AUTOSAR XML (schema 4-0-3)
standard types defined: Boolean, UInt16, UInt32, UInt8
package /AUTOSAR_Platform/DataConstrs
  range DC_Boolean: raw 0..1
  range DC_UInt16: raw 0..65535
  range DC_UInt8: raw 0..255
package /PATAC/MSM/ComponentTypes
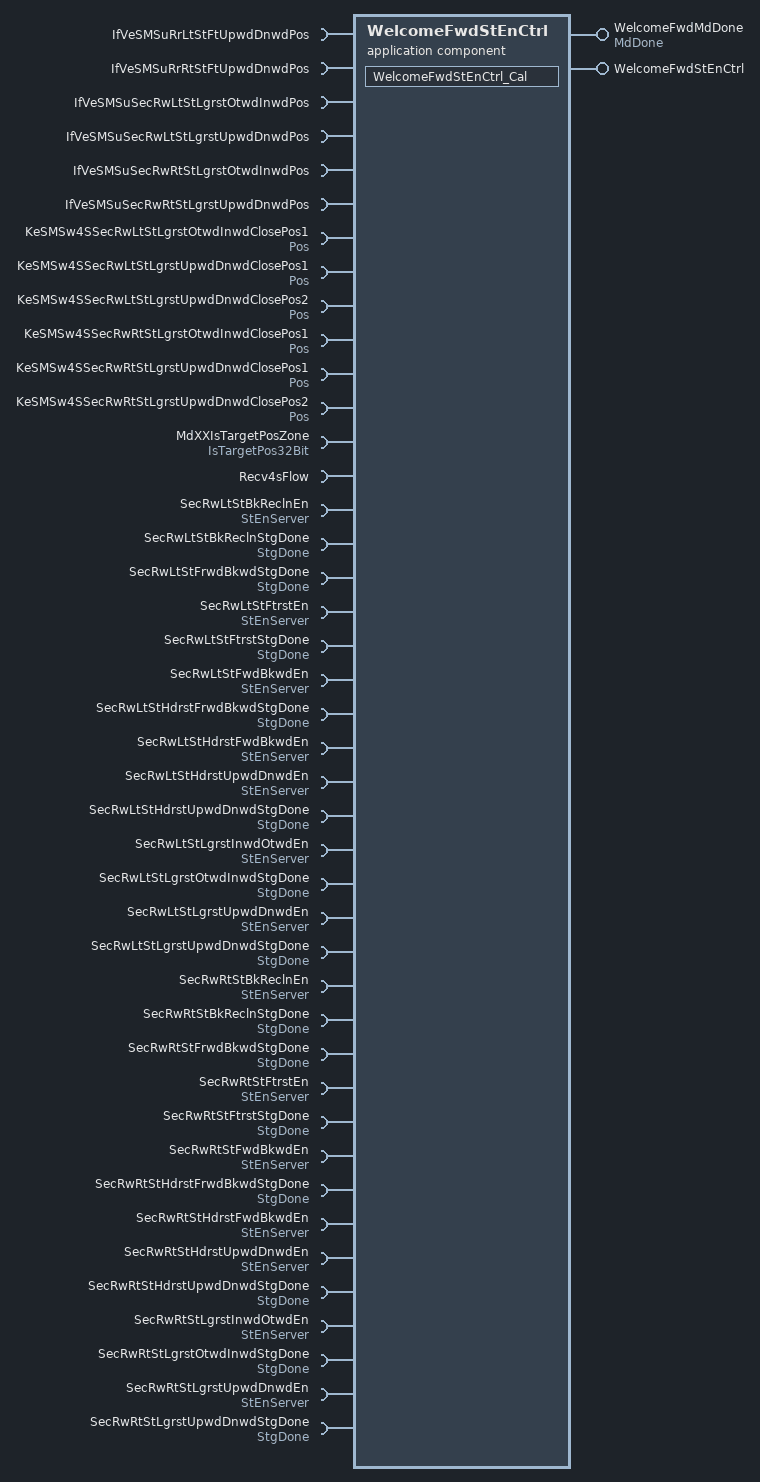
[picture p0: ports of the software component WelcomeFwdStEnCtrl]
  application sw component type WelcomeFwdStEnCtrl
    provide port WelcomeFwdMdDone: nonqueued-sender-com-spec{data-element=MdDone/Val, init-value=0}, provided-interface=MdDone
    provide port WelcomeFwdStEnCtrl: server-com-spec{operation=WelcomeFwdStEnCtrl/Cal, queue-length=1}, provided-interface=WelcomeFwdStEnCtrl
    42 x require port:
      IfVeSMSuRrLtStFtUpwdDnwdPos: nonqueued-receiver-com-spec{data-element=IfVeSMSuRrLtStFtUpwdDnwdPos/Val, filter=data-filter-type=ALWAYS, init-value=0}, required-interface=IfVeSMSuRrLtStFtUpwdDnwdPos
      IfVeSMSuRrRtStFtUpwdDnwdPos: nonqueued-receiver-com-spec{data-element=IfVeSMSuRrRtStFtUpwdDnwdPos/Val, filter=data-filter-type=ALWAYS, init-value=0}, required-interface=IfVeSMSuRrRtStFtUpwdDnwdPos
      IfVeSMSuSecRwLtStLgrstOtwdInwdPos: nonqueued-receiver-com-spec{data-element=IfVeSMSuSecRwLtStLgrstOtwdInwdPos/Val, filter=data-filter-type=ALWAYS, init-value=0}, required-interface=IfVeSMSuSecRwLtStLgrstOtwdInwdPos
      IfVeSMSuSecRwLtStLgrstUpwdDnwdPos: nonqueued-receiver-com-spec{data-element=IfVeSMSuSecRwLtStLgrstUpwdDnwdPos/Val, filter=data-filter-type=ALWAYS, init-value=0}, required-interface=IfVeSMSuSecRwLtStLgrstUpwdDnwdPos
      IfVeSMSuSecRwRtStLgrstOtwdInwdPos: nonqueued-receiver-com-spec{data-element=IfVeSMSuSecRwRtStLgrstOtwdInwdPos/Val, filter=data-filter-type=ALWAYS, init-value=0}, required-interface=IfVeSMSuSecRwRtStLgrstOtwdInwdPos
      IfVeSMSuSecRwRtStLgrstUpwdDnwdPos: nonqueued-receiver-com-spec{data-element=IfVeSMSuSecRwRtStLgrstUpwdDnwdPos/Val, filter=data-filter-type=ALWAYS, init-value=0}, required-interface=IfVeSMSuSecRwRtStLgrstUpwdDnwdPos
      KeSMSw4SSecRwLtStLgrstOtwdInwdClosePos1: parameter-require-com-spec{init-value=0, parameter=Val}, required-interface=Pos
      KeSMSw4SSecRwLtStLgrstUpwdDnwdClosePos1: parameter-require-com-spec{init-value=0, parameter=Val}, required-interface=Pos
      KeSMSw4SSecRwLtStLgrstUpwdDnwdClosePos2: parameter-require-com-spec{init-value=0, parameter=Val}, required-interface=Pos
      KeSMSw4SSecRwRtStLgrstOtwdInwdClosePos1: parameter-require-com-spec{init-value=0, parameter=Val}, required-interface=Pos
      KeSMSw4SSecRwRtStLgrstUpwdDnwdClosePos1: parameter-require-com-spec{init-value=0, parameter=Val}, required-interface=Pos
      KeSMSw4SSecRwRtStLgrstUpwdDnwdClosePos2: parameter-require-com-spec{init-value=0, parameter=Val}, required-interface=Pos
      MdXXIsTargetPosZone: nonqueued-receiver-com-spec{data-element=IsTargetPos32Bit/Val, filter=data-filter-type=ALWAYS, init-value=0}, required-interface=IsTargetPos32Bit
      Recv4sFlow: client-com-spec=Recv4sFlow/Cal, required-interface=Recv4sFlow
      SecRwLtStBkReclnEn: required-com-specs=[Clear, Get, Set], required-interface=StEnServer
      SecRwLtStBkReclnStgDone: nonqueued-receiver-com-spec{data-element=StgDone/Val, filter=data-filter-type=ALWAYS, init-value=0}, required-interface=StgDone
      SecRwLtStFrwdBkwdStgDone: nonqueued-receiver-com-spec{data-element=StgDone/Val, filter=data-filter-type=ALWAYS, init-value=0}, required-interface=StgDone
      SecRwLtStFtrstEn: required-com-specs=[Clear, Get, Set], required-interface=StEnServer
      SecRwLtStFtrstStgDone: nonqueued-receiver-com-spec{data-element=StgDone/Val, filter=data-filter-type=ALWAYS, init-value=0}, required-interface=StgDone
      SecRwLtStFwdBkwdEn: required-com-specs=[Clear, Get, Set], required-interface=StEnServer
      SecRwLtStHdrstFrwdBkwdStgDone: nonqueued-receiver-com-spec{data-element=StgDone/Val, filter=data-filter-type=ALWAYS, init-value=0}, required-interface=StgDone
      SecRwLtStHdrstFwdBkwdEn: required-com-specs=[Clear, Get, Set], required-interface=StEnServer
      SecRwLtStHdrstUpwdDnwdEn: required-com-specs=[Clear, Get, Set], required-interface=StEnServer
      SecRwLtStHdrstUpwdDnwdStgDone: nonqueued-receiver-com-spec{data-element=StgDone/Val, filter=data-filter-type=ALWAYS, init-value=0}, required-interface=StgDone
      SecRwLtStLgrstInwdOtwdEn: required-com-specs=[Clear, Get, Set], required-interface=StEnServer
      SecRwLtStLgrstOtwdInwdStgDone: nonqueued-receiver-com-spec{data-element=StgDone/Val, filter=data-filter-type=ALWAYS, init-value=0}, required-interface=StgDone
      SecRwLtStLgrstUpwdDnwdEn: required-com-specs=[Clear, Get, Set], required-interface=StEnServer
      SecRwLtStLgrstUpwdDnwdStgDone: nonqueued-receiver-com-spec{data-element=StgDone/Val, filter=data-filter-type=ALWAYS, init-value=0}, required-interface=StgDone
      SecRwRtStBkReclnEn: required-com-specs=[Clear, Get, Set], required-interface=StEnServer
      SecRwRtStBkReclnStgDone: nonqueued-receiver-com-spec{data-element=StgDone/Val, filter=data-filter-type=ALWAYS, init-value=0}, required-interface=StgDone
      SecRwRtStFrwdBkwdStgDone: nonqueued-receiver-com-spec{data-element=StgDone/Val, filter=data-filter-type=ALWAYS, init-value=0}, required-interface=StgDone
      SecRwRtStFtrstEn: required-com-specs=[Clear, Get, Set], required-interface=StEnServer
      SecRwRtStFtrstStgDone: nonqueued-receiver-com-spec{data-element=StgDone/Val, filter=data-filter-type=ALWAYS, init-value=0}, required-interface=StgDone
      SecRwRtStFwdBkwdEn: required-com-specs=[Clear, Get, Set], required-interface=StEnServer
      SecRwRtStHdrstFrwdBkwdStgDone: nonqueued-receiver-com-spec{data-element=StgDone/Val, filter=data-filter-type=ALWAYS, init-value=0}, required-interface=StgDone
      SecRwRtStHdrstFwdBkwdEn: required-com-specs=[Clear, Get, Set], required-interface=StEnServer
      SecRwRtStHdrstUpwdDnwdEn: required-com-specs=[Clear, Get, Set], required-interface=StEnServer
      SecRwRtStHdrstUpwdDnwdStgDone: nonqueued-receiver-com-spec{data-element=StgDone/Val, filter=data-filter-type=ALWAYS, init-value=0}, required-interface=StgDone
      SecRwRtStLgrstInwdOtwdEn: required-com-specs=[Clear, Get, Set], required-interface=StEnServer
      SecRwRtStLgrstOtwdInwdStgDone: nonqueued-receiver-com-spec{data-element=StgDone/Val, filter=data-filter-type=ALWAYS, init-value=0}, required-interface=StgDone
      SecRwRtStLgrstUpwdDnwdEn: required-com-specs=[Clear, Get, Set], required-interface=StEnServer
      SecRwRtStLgrstUpwdDnwdStgDone: nonqueued-receiver-com-spec{data-element=StgDone/Val, filter=data-filter-type=ALWAYS, init-value=0}, required-interface=StgDone
    behavior WelcomeFwdStEnCtrl_InternalBehavior
      operation invoked event OIT_WelcomeFwdStEnCtrl_Cal_WelcomeFwdStEnCtrl_Cal: start-on-event=WelcomeFwdStEnCtrl_Cal, operation=WelcomeFwdStEnCtrl.Cal
      runnable WelcomeFwdStEnCtrl_Cal
        data-receive-point-by-arguments:
          21 x access:
            REC_IfVeSMSuRrLtStFtUpwdDnwdPos_Val: accessed-variable=IfVeSMSuRrLtStFtUpwdDnwdPos.Val
            REC_IfVeSMSuRrRtStFtUpwdDnwdPos_Val: accessed-variable=IfVeSMSuRrRtStFtUpwdDnwdPos.Val
            REC_IfVeSMSuSecRwLtStLgrstOtwdInwdPos_Val: accessed-variable=IfVeSMSuSecRwLtStLgrstOtwdInwdPos.Val
            REC_IfVeSMSuSecRwLtStLgrstUpwdDnwdPos_Val: accessed-variable=IfVeSMSuSecRwLtStLgrstUpwdDnwdPos.Val
            REC_IfVeSMSuSecRwRtStLgrstOtwdInwdPos_Val: accessed-variable=IfVeSMSuSecRwRtStLgrstOtwdInwdPos.Val
            REC_IfVeSMSuSecRwRtStLgrstUpwdDnwdPos_Val: accessed-variable=IfVeSMSuSecRwRtStLgrstUpwdDnwdPos.Val
            REC_MdXXIsTargetPosZone_Val: accessed-variable=MdXXIsTargetPosZone.Val
            REC_SecRwLtStBkReclnStgDone_Val: accessed-variable=SecRwLtStBkReclnStgDone.Val
            REC_SecRwLtStFrwdBkwdStgDone_Val: accessed-variable=SecRwLtStFrwdBkwdStgDone.Val
            REC_SecRwLtStFtrstStgDone_Val: accessed-variable=SecRwLtStFtrstStgDone.Val
            REC_SecRwLtStHdrstFrwdBkwdStgDone_Val: accessed-variable=SecRwLtStHdrstFrwdBkwdStgDone.Val
            REC_SecRwLtStHdrstUpwdDnwdStgDone_Val: accessed-variable=SecRwLtStHdrstUpwdDnwdStgDone.Val
            REC_SecRwLtStLgrstOtwdInwdStgDone_Val: accessed-variable=SecRwLtStLgrstOtwdInwdStgDone.Val
            REC_SecRwLtStLgrstUpwdDnwdStgDone_Val: accessed-variable=SecRwLtStLgrstUpwdDnwdStgDone.Val
            REC_SecRwRtStBkReclnStgDone_Val: accessed-variable=SecRwRtStBkReclnStgDone.Val
            REC_SecRwRtStFrwdBkwdStgDone_Val: accessed-variable=SecRwRtStFrwdBkwdStgDone.Val
            REC_SecRwRtStFtrstStgDone_Val: accessed-variable=SecRwRtStFtrstStgDone.Val
            REC_SecRwRtStHdrstFrwdBkwdStgDone_Val: accessed-variable=SecRwRtStHdrstFrwdBkwdStgDone.Val
            REC_SecRwRtStHdrstUpwdDnwdStgDone_Val: accessed-variable=SecRwRtStHdrstUpwdDnwdStgDone.Val
            REC_SecRwRtStLgrstOtwdInwdStgDone_Val: accessed-variable=SecRwRtStLgrstOtwdInwdStgDone.Val
            REC_SecRwRtStLgrstUpwdDnwdStgDone_Val: accessed-variable=SecRwRtStLgrstUpwdDnwdStgDone.Val
        data-send-points:
          access SEND_WelcomeFwdMdDone_Val: accessed-variable=WelcomeFwdMdDone.Val
        6 x parameter access:
          PA_KeSMSw4SSecRwLtStLgrstOtwdInwdClosePos1_Val: accessed-parameter=KeSMSw4SSecRwLtStLgrstOtwdInwdClosePos1.Val
          PA_KeSMSw4SSecRwLtStLgrstUpwdDnwdClosePos1_Val: accessed-parameter=KeSMSw4SSecRwLtStLgrstUpwdDnwdClosePos1.Val
          PA_KeSMSw4SSecRwLtStLgrstUpwdDnwdClosePos2_Val: accessed-parameter=KeSMSw4SSecRwLtStLgrstUpwdDnwdClosePos2.Val
          PA_KeSMSw4SSecRwRtStLgrstOtwdInwdClosePos1_Val: accessed-parameter=KeSMSw4SSecRwRtStLgrstOtwdInwdClosePos1.Val
          PA_KeSMSw4SSecRwRtStLgrstUpwdDnwdClosePos1_Val: accessed-parameter=KeSMSw4SSecRwRtStLgrstUpwdDnwdClosePos1.Val
          PA_KeSMSw4SSecRwRtStLgrstUpwdDnwdClosePos2_Val: accessed-parameter=KeSMSw4SSecRwRtStLgrstUpwdDnwdClosePos2.Val
        29 x sync call, all with timeout=0:
          SC_Recv4sFlow_Cal: operation=Recv4sFlow.Cal
          SC_SecRwLtStBkReclnEn_Clear: operation=SecRwLtStBkReclnEn.Clear
          SC_SecRwLtStBkReclnEn_Set: operation=SecRwLtStBkReclnEn.Set
          SC_SecRwLtStFtrstEn_Clear: operation=SecRwLtStFtrstEn.Clear
          SC_SecRwLtStFtrstEn_Set: operation=SecRwLtStFtrstEn.Set
          SC_SecRwLtStFwdBkwdEn_Clear: operation=SecRwLtStFwdBkwdEn.Clear
          SC_SecRwLtStFwdBkwdEn_Set: operation=SecRwLtStFwdBkwdEn.Set
          SC_SecRwLtStHdrstFwdBkwdEn_Clear: operation=SecRwLtStHdrstFwdBkwdEn.Clear
          SC_SecRwLtStHdrstFwdBkwdEn_Set: operation=SecRwLtStHdrstFwdBkwdEn.Set
          SC_SecRwLtStHdrstUpwdDnwdEn_Clear: operation=SecRwLtStHdrstUpwdDnwdEn.Clear
          SC_SecRwLtStHdrstUpwdDnwdEn_Set: operation=SecRwLtStHdrstUpwdDnwdEn.Set
          SC_SecRwLtStLgrstInwdOtwdEn_Clear: operation=SecRwLtStLgrstInwdOtwdEn.Clear
          SC_SecRwLtStLgrstInwdOtwdEn_Set: operation=SecRwLtStLgrstInwdOtwdEn.Set
          SC_SecRwLtStLgrstUpwdDnwdEn_Clear: operation=SecRwLtStLgrstUpwdDnwdEn.Clear
          SC_SecRwLtStLgrstUpwdDnwdEn_Set: operation=SecRwLtStLgrstUpwdDnwdEn.Set
          SC_SecRwRtStBkReclnEn_Clear: operation=SecRwRtStBkReclnEn.Clear
          SC_SecRwRtStBkReclnEn_Set: operation=SecRwRtStBkReclnEn.Set
          SC_SecRwRtStFtrstEn_Clear: operation=SecRwRtStFtrstEn.Clear
          SC_SecRwRtStFtrstEn_Set: operation=SecRwRtStFtrstEn.Set
          SC_SecRwRtStFwdBkwdEn_Clear: operation=SecRwRtStFwdBkwdEn.Clear
          SC_SecRwRtStFwdBkwdEn_Set: operation=SecRwRtStFwdBkwdEn.Set
          SC_SecRwRtStHdrstFwdBkwdEn_Clear: operation=SecRwRtStHdrstFwdBkwdEn.Clear
          SC_SecRwRtStHdrstFwdBkwdEn_Set: operation=SecRwRtStHdrstFwdBkwdEn.Set
          SC_SecRwRtStHdrstUpwdDnwdEn_Clear: operation=SecRwRtStHdrstUpwdDnwdEn.Clear
          SC_SecRwRtStHdrstUpwdDnwdEn_Set: operation=SecRwRtStHdrstUpwdDnwdEn.Set
          SC_SecRwRtStLgrstInwdOtwdEn_Clear: operation=SecRwRtStLgrstInwdOtwdEn.Clear
          SC_SecRwRtStLgrstInwdOtwdEn_Set: operation=SecRwRtStLgrstInwdOtwdEn.Set
          SC_SecRwRtStLgrstUpwdDnwdEn_Clear: operation=SecRwRtStLgrstUpwdDnwdEn.Clear
          SC_SecRwRtStLgrstUpwdDnwdEn_Set: operation=SecRwRtStLgrstUpwdDnwdEn.Set
  swc implementation WelcomeFwdStEnCtrl_Implementation: behavior=WelcomeFwdStEnCtrl_InternalBehavior
    code-descriptors:
      code Default: artifact-descriptors=autosar-engineering-object={short-label=Default, category=SWSRC}
package /PATAC/MSM/ModeAdjust/CalPortInterface
  parameter interface Pos
    parameter data prototype Val: sw-calibration-access=READ-WRITE, type=UInt16
package /PATAC/MSM/ModeAdjust/PortInterface
  client server interface Recv4sFlow
    operation Cal
      19 x arg, all with server-argument-impl-policy=USE-ARGUMENT-TYPE:
        LgrstUpwdDnwdPos: type=UInt16, direction=IN
        LgrstOtwdInwdPos: type=UInt16, direction=IN
        FtUpwdDnwdPos: type=UInt16, direction=IN
        CloseDnwdPos1: type=UInt16, direction=IN
        CloseDnwdPos2: type=UInt16, direction=IN
        CloseOtwdPos1: type=UInt16, direction=IN
        LgrstInwdStgDone: type=Boolean, direction=IN
        LgrstUpwdStgDone: type=Boolean, direction=IN
        FtrstStgDone: type=Boolean, direction=IN
        BkReclnStgDone: type=Boolean, direction=IN
        HdrstFwdBkwdStgDone: type=Boolean, direction=IN
        HdrstupwdDnwdStgDone: type=Boolean, direction=IN
        Failflg: type=Boolean, direction=OUT
        LgrstInwdOtwdEn: type=Boolean, direction=OUT
        LgrstUpwdDnwdEn: type=Boolean, direction=OUT
        FtrstEn: type=Boolean, direction=OUT
        BkReclnEn: type=Boolean, direction=OUT
        HdrstFrwdBkwdEn: type=Boolean, direction=OUT
        HdrstUpwdDnwdEn: type=Boolean, direction=OUT
  client server interface StEnServer
    operation Clear
      arg data: type=UInt8, direction=IN, server-argument-impl-policy=USE-ARGUMENT-TYPE
    operation Get
      arg data: type=UInt32, direction=OUT, server-argument-impl-policy=USE-ARGUMENT-TYPE
    operation Set
      arg data: type=UInt8, direction=IN, server-argument-impl-policy=USE-ARGUMENT-TYPE
  client server interface WelcomeFwdStEnCtrl
    operation Cal
  sender receiver interface IsTargetPos32Bit: invalidation-policy{data-element=IsTargetPos32Bit/Val, handle-invalid=DONT-INVALIDATE}
    data Val: type=UInt32
  sender receiver interface MdDone: invalidation-policy{data-element=MdDone/Val, handle-invalid=DONT-INVALIDATE}
    data Val: type=UInt8
  sender receiver interface StgDone: invalidation-policy{data-element=StgDone/Val, handle-invalid=DONT-INVALIDATE}
    data Val: type=Boolean
package /PATAC/MSM/PortInterfaces
  6 x sender receiver interface:
    IfVeSMSuRrLtStFtUpwdDnwdPos: invalidation-policy{data-element=IfVeSMSuRrLtStFtUpwdDnwdPos/Val, handle-invalid=DONT-INVALIDATE}
      data Val: type=UInt16
    IfVeSMSuRrRtStFtUpwdDnwdPos: invalidation-policy{data-element=IfVeSMSuRrRtStFtUpwdDnwdPos/Val, handle-invalid=DONT-INVALIDATE}
      data Val: type=UInt16
    IfVeSMSuSecRwLtStLgrstOtwdInwdPos: invalidation-policy{data-element=IfVeSMSuSecRwLtStLgrstOtwdInwdPos/Val, handle-invalid=DONT-INVALIDATE}
      data Val: type=UInt16
    IfVeSMSuSecRwLtStLgrstUpwdDnwdPos: invalidation-policy{data-element=IfVeSMSuSecRwLtStLgrstUpwdDnwdPos/Val, handle-invalid=DONT-INVALIDATE}
      data Val: type=UInt16
    IfVeSMSuSecRwRtStLgrstOtwdInwdPos: invalidation-policy{data-element=IfVeSMSuSecRwRtStLgrstOtwdInwdPos/Val, handle-invalid=DONT-INVALIDATE}
      data Val: type=UInt16
    IfVeSMSuSecRwRtStLgrstUpwdDnwdPos: invalidation-policy{data-element=IfVeSMSuSecRwRtStLgrstUpwdDnwdPos/Val, handle-invalid=DONT-INVALIDATE}
      data Val: type=UInt16
